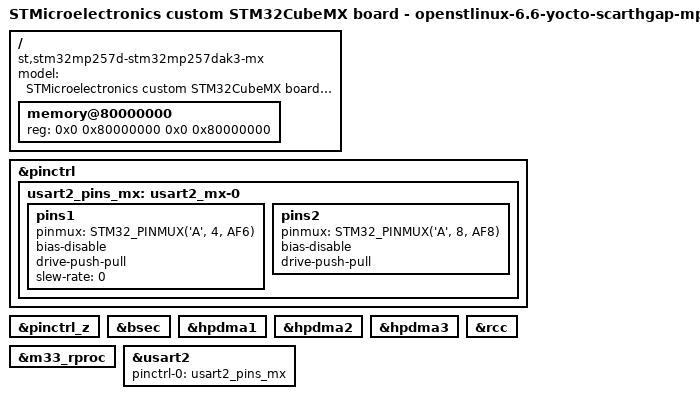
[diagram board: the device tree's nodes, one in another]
// SPDX-License-Identifier: (GPL-2.0-only OR BSD-3-Clause)
/*
 * Copyright (C) 2025, STMicroelectronics - All Rights Reserved
 * Author: STM32CubeMX code generation for STMicroelectronics.
 */

/* For more information on Device Tree configuration, please refer to
 * https://wiki.st.com/stm32mpu/wiki/Category:Device_tree_configuration
 */

/dts-v1/;

#include <dt-bindings/pinctrl/stm32-pinfunc.h>
#include <dt-bindings/clock/stm32mp25-clksrc.h>
#include "stm32mp257.dtsi"
#include "stm32mp257d-stm32mp257dak3-mx-rcc.dtsi"
#include "stm32mp257d-stm32mp257dak3-mx-resmem.dtsi"
#include "stm32mp257d-stm32mp257dak3-mx-rif.dtsi"
#include "stm32mp25xxak-pinctrl.dtsi"

/* USER CODE BEGIN includes */
/* USER CODE END includes */

/ {
	model = "STMicroelectronics custom STM32CubeMX board - openstlinux-6.6-yocto-scarthgap-mpu-v25.06.11";
	compatible = "st,stm32mp257d-stm32mp257dak3-mx", "st,stm32mp257";

	memory@80000000 {
		device_type = "memory";
		reg = <0x0 0x80000000 0x0 0x80000000>;

		/* USER CODE BEGIN memory */
		/* USER CODE END memory */
	};

	/* USER CODE BEGIN root */
	/* USER CODE END root */

}; /*root*/

&pinctrl {
	usart2_pins_mx: usart2_mx-0 {
		pins1 {
			pinmux = <STM32_PINMUX('A', 4, AF6)>; /* USART2_TX */
			bias-disable;
			drive-push-pull;
			slew-rate = <0>;
		};
		pins2 {
			pinmux = <STM32_PINMUX('A', 8, AF8)>; /* USART2_RX */
			bias-disable;
			drive-push-pull;
		};
	};

	/* USER CODE BEGIN pinctrl */
	/* USER CODE END pinctrl */
};

&pinctrl_z {
	/* USER CODE BEGIN pinctrl_z */
	/* USER CODE END pinctrl_z */
};

&bsec {
	status = "okay";

	/* USER CODE BEGIN bsec */
	/* USER CODE END bsec */
};

&hpdma1 {
	status = "okay";

	/* USER CODE BEGIN hpdma1 */
	/* USER CODE END hpdma1 */
};

&hpdma2 {
	status = "okay";

	/* USER CODE BEGIN hpdma2 */
	/* USER CODE END hpdma2 */
};

&hpdma3 {
	status = "okay";

	/* USER CODE BEGIN hpdma3 */
	/* USER CODE END hpdma3 */
};

&m33_rproc {
	status = "okay";

	/* USER CODE BEGIN m33_rproc */
	/* USER CODE END m33_rproc */
};

&rcc {
	status = "okay";

	/* USER CODE BEGIN rcc */
	/* USER CODE END rcc */
};

&usart2 {
	pinctrl-names = "default";
	pinctrl-0 = <&usart2_pins_mx>;
	status = "okay";

	/* USER CODE BEGIN usart2 */
	/* USER CODE END usart2 */
};

/* USER CODE BEGIN addons */
/* USER CODE END addons */

